AUTOSAR XML (schema 00051)
package /Components
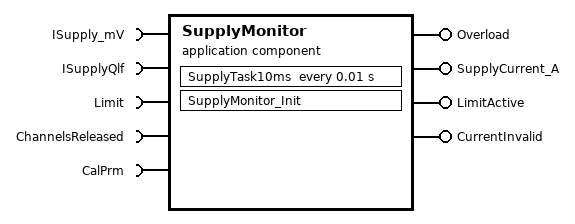
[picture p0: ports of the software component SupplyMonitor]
  application sw component type SupplyMonitor
    4 x require port:
      ISupply_mV: nonqueued-receiver-com-spec{data-element=ISupply_mV, init-value=0}, required-interface=ISupply_mV
      ISupplyQlf: nonqueued-receiver-com-spec{data-element=ISupplyQlf, init-value=0}, required-interface=ISupplyQlf
      Limit: nonqueued-receiver-com-spec{data-element=Limit, init-value=0}, required-interface=Limit
      ChannelsReleased: nonqueued-receiver-com-spec{data-element=ChannelsReleased, init-value=0}, required-interface=ChannelsReleased
    4 x provide port:
      Overload: nonqueued-sender-com-spec{data-element=Overload, init-value=0}, provided-interface=Overload
      SupplyCurrent_A: nonqueued-sender-com-spec{data-element=SupplyCurrent_A, init-value=0}, provided-interface=SupplyCurrent_A
      LimitActive: nonqueued-sender-com-spec{data-element=LimitActive, init-value=0}, provided-interface=LimitActive
      CurrentInvalid: nonqueued-sender-com-spec{data-element=CurrentInvalid, init-value=0}, provided-interface=CurrentInvalid
    require port CalPrm: required-interface=CalPrm
      required-com-specs:
        init-value=CalPrm_MinCurrent_mA:100, parameter=MinCurrent_mA
        init-value=CalPrm_OverloadHyst_mA:200, parameter=OverloadHyst_mA
        init-value=CalPrm_OverloadThd_mA:1280, parameter=OverloadThd_mA
        init-value=CalPrm_SupplyCurrentFilter:0.0078125, parameter=SupplyCurrentFilter
        init-value=CalPrm_SupplyCurrentGain:1, parameter=SupplyCurrentGain
        init-value=CalPrm_CurrentInvalid_cycles:20, parameter=CurrentInvalid_cycles
        init-value=CalPrm_MinCurrentTime_cycles:20, parameter=MinCurrentTime_cycles
    behavior SupplyMonitor_IB: handle-termination-and-restart=NO-SUPPORT
      timing event Event_SupplyTask10ms: start-on-event=SupplyTask10ms, period=0.01
      runnable SupplyMonitor_Init
      runnable SupplyTask10ms
        data-receive-point-by-arguments:
          4 x access:
            IN_ChannelsReleased_ChannelsReleased: accessed-variable=ChannelsReleased.ChannelsReleased
            IN_ISupplyQlf_ISupplyQlf: accessed-variable=ISupplyQlf.ISupplyQlf
            IN_ISupply_mV_ISupply_mV: accessed-variable=ISupply_mV.ISupply_mV
            IN_Limit_Limit: accessed-variable=Limit.Limit
        data-send-points:
          4 x access:
            OUT_Overload_Overload: accessed-variable=Overload.Overload
            OUT_SupplyCurrent_A_SupplyCurrent_A: accessed-variable=SupplyCurrent_A.SupplyCurrent_A
            OUT_LimitActive_LimitActive: accessed-variable=LimitActive.LimitActive
            OUT_CurrentInvalid_CurrentInvalid: accessed-variable=CurrentInvalid.CurrentInvalid
        7 x parameter access:
          CALPRM_CalPrm_CurrentInvalid_cycles: accessed-parameter=CalPrm.CurrentInvalid_cycles
          CALPRM_CalPrm_MinCurrentTime_cycles: accessed-parameter=CalPrm.MinCurrentTime_cycles
          CALPRM_CalPrm_MinCurrent_mA: accessed-parameter=CalPrm.MinCurrent_mA
          CALPRM_CalPrm_OverloadHyst_mA: accessed-parameter=CalPrm.OverloadHyst_mA
          CALPRM_CalPrm_OverloadThd_mA: accessed-parameter=CalPrm.OverloadThd_mA
          CALPRM_CalPrm_SupplyCurrentFilter: accessed-parameter=CalPrm.SupplyCurrentFilter
          CALPRM_CalPrm_SupplyCurrentGain: accessed-parameter=CalPrm.SupplyCurrentGain
